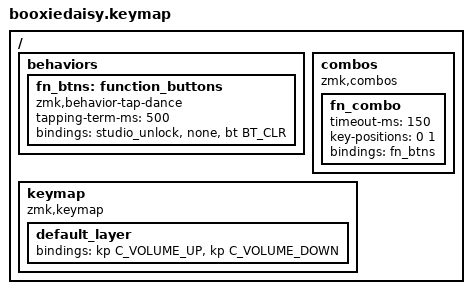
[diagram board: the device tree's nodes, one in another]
#include <behaviors.dtsi>
#include <dt-bindings/zmk/keys.h>
#include <dt-bindings/zmk/bt.h>
#include <dt-bindings/zmk/ext_power.h>

#define DEF_L 0

/ {
    behaviors {
        fn_btns: function_buttons {
            compatible = "zmk,behavior-tap-dance";
            #binding-cells = <0>;
            tapping-term-ms = <500>;
            bindings = <&studio_unlock>, <&none>, <&bt BT_CLR>;
        };
    };

    combos {
        compatible = "zmk,combos";
        fn_combo {
            timeout-ms = <150>;
            key-positions = <0 1>;
            bindings = <&fn_btns>;
        };
    };

    keymap {
        compatible = "zmk,keymap";
        default_layer {
            bindings = <
                &kp C_VOLUME_UP    &kp C_VOLUME_DOWN
            >;
        };

    };
};
